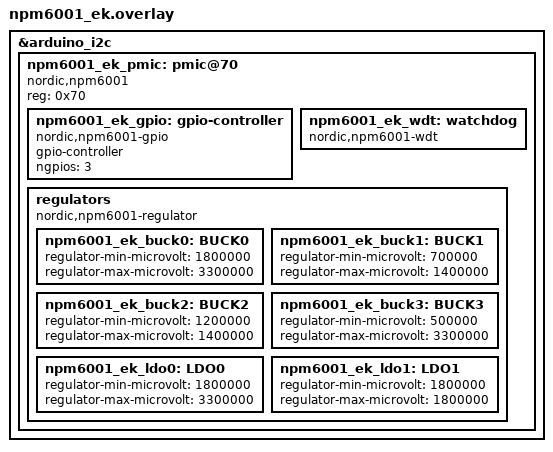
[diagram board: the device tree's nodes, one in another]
/*
 * Copyright (C) 2022 Nordic Semiconductor ASA
 * SPDX-License-Identifier: Apache-2.0
 */

&arduino_i2c {
	npm6001_ek_pmic: pmic@70 {
		compatible = "nordic,npm6001";
		reg = <0x70>;

		npm6001_ek_gpio: gpio-controller {
			compatible = "nordic,npm6001-gpio";
			gpio-controller;
			#gpio-cells = <2>;
			ngpios = <3>;
		};

		npm6001_ek_wdt: watchdog {
			compatible = "nordic,npm6001-wdt";
		};

		regulators {
			compatible = "nordic,npm6001-regulator";

			/* limits are set to min/max allowed values */

			npm6001_ek_buck0: BUCK0 {
				regulator-min-microvolt = <1800000>;
				regulator-max-microvolt = <3300000>;
			};

			npm6001_ek_buck1: BUCK1 {
				regulator-min-microvolt = <700000>;
				regulator-max-microvolt = <1400000>;
			};

			npm6001_ek_buck2: BUCK2 {
				regulator-min-microvolt = <1200000>;
				regulator-max-microvolt = <1400000>;
			};

			npm6001_ek_buck3: BUCK3 {
				regulator-min-microvolt = <500000>;
				regulator-max-microvolt = <3300000>;
			};

			npm6001_ek_ldo0: LDO0 {
				regulator-min-microvolt = <1800000>;
				regulator-max-microvolt = <3300000>;
			};

			npm6001_ek_ldo1: LDO1 {
				regulator-min-microvolt = <1800000>;
				regulator-max-microvolt = <1800000>;
			};
		};
	};
};
